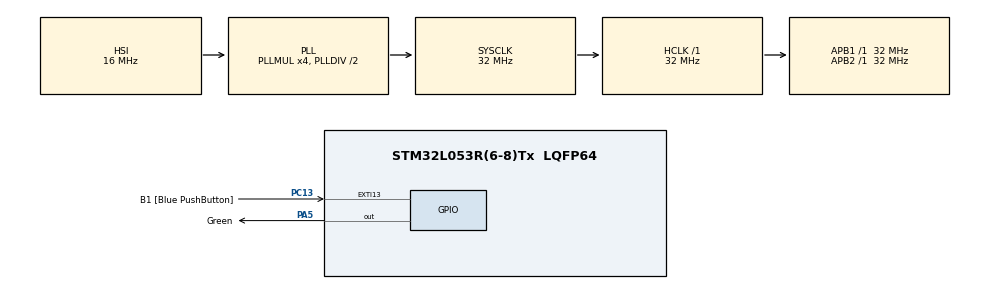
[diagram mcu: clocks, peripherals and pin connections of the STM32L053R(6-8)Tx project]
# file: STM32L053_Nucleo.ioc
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Mcu.Family=STM32L0
Mcu.Name=STM32L053R(6-8)Tx
Mcu.Package=LQFP64
PA13.GPIO_Label=TMS
PA13.Mode=Serial_Wire
PA13.Signal=SYS_SWDIO
PA14.GPIO_Label=TCK
PA14.Mode=Serial_Wire
PA14.Signal=SYS_SWCLK
PA2.GPIO_Label=USART_TX
PA2.Signal=USART2_TX
PA3.GPIO_Label=USART_RX
PA3.Signal=USART2_RX
PA5.GPIO_Label=Green
PA5.Signal=GPIO_Output
PC13.GPIO_Label=B1 [Blue PushButton]
PC13.GPIO_ModeDefaultEXTI=GPIO_MODE_IT_FALLING
PC13.Signal=GPXTI13
PC14-OSC32_IN.Signal=RCC_OSC32_IN
PC15-OSC32_OUT.Signal=RCC_OSC32_OUT
PH0-OSC_IN.Signal=RCC_OSC_IN
PH1-OSC_OUT.Signal=RCC_OSC_OUT
ProjectManager.HeapSize=0x200
ProjectManager.StackSize=0x400
ProjectManager.TargetToolchain=SW4STM32
RCC.AHBFreq_Value=32000000
RCC.APB1Freq_Value=32000000
RCC.APB1TimFreq_Value=32000000
RCC.APB2Freq_Value=32000000
RCC.APB2TimFreq_Value=32000000
RCC.HCLKFreq_Value=32000000
RCC.HSE_VALUE=8000000
RCC.HSI16_VALUE=16000000
RCC.HSI48_VALUE=48000000
RCC.HSI_VALUE=16000000
RCC.LSEState=RCC_LSE_ON
RCC.LSE_VALUE=32768
RCC.MSI_VALUE=2097000
RCC.PLLMUL=RCC_PLLMUL_4
RCC.SYSCLKFreq_VALUE=32000000
RCC.SYSCLKSource=RCC_SYSCLKSOURCE_PLLCLK
RCC.VCOOutputFreq_Value=64000000
board=NUCLEO-L053R8

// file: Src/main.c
/**
  ******************************************************************************
  * File Name          : main.c
  * Description        : Main program body
  ******************************************************************************
  ** This notice applies to any and all portions of this file
  * that are not between comment pairs USER CODE BEGIN and
  * USER CODE END. Other portions of this file, whether
  * inserted by the user or by software development tools
  * are owned by their respective copyright owners.
  *
  * COPYRIGHT(c) 2017 STMicroelectronics
  *
  * Redistribution and use in source and binary forms, with or without modification,
  * are permitted provided that the following conditions are met:
  *   1. Redistributions of source code must retain the above copyright notice,
  *      this list of conditions and the following disclaimer.
  *   2. Redistributions in binary form must reproduce the above copyright notice,
  *      this list of conditions and the following disclaimer in the documentation
  *      and/or other materials provided with the distribution.
  *   3. Neither the name of STMicroelectronics nor the names of its contributors
  *      may be used to endorse or promote products derived from this software
  *      without specific prior written permission.
  *
  * THIS SOFTWARE IS PROVIDED BY THE COPYRIGHT HOLDERS AND CONTRIBUTORS "AS IS"
  * AND ANY EXPRESS OR IMPLIED WARRANTIES, INCLUDING, BUT NOT LIMITED TO, THE
  * IMPLIED WARRANTIES OF MERCHANTABILITY AND FITNESS FOR A PARTICULAR PURPOSE ARE
  * DISCLAIMED. IN NO EVENT SHALL THE COPYRIGHT HOLDER OR CONTRIBUTORS BE LIABLE
  * FOR ANY DIRECT, INDIRECT, INCIDENTAL, SPECIAL, EXEMPLARY, OR CONSEQUENTIAL
  * DAMAGES (INCLUDING, BUT NOT LIMITED TO, PROCUREMENT OF SUBSTITUTE GOODS OR
  * SERVICES; LOSS OF USE, DATA, OR PROFITS; OR BUSINESS INTERRUPTION) HOWEVER
  * CAUSED AND ON ANY THEORY OF LIABILITY, WHETHER IN CONTRACT, STRICT LIABILITY,
  * OR TORT (INCLUDING NEGLIGENCE OR OTHERWISE) ARISING IN ANY WAY OUT OF THE USE
  * OF THIS SOFTWARE, EVEN IF ADVISED OF THE POSSIBILITY OF SUCH DAMAGE.
  *
  ******************************************************************************
  */
#include "main.h"
#include "stm32l0xx_hal.h"

/* USER CODE BEGIN PV */
/* Private variables ---------------------------------------------------------*/

/* USER CODE END PV */

void SystemClock_Config(void);
static void MX_GPIO_Init(void);

/* USER CODE BEGIN PFP */
/* Private function prototypes -----------------------------------------------*/

/* USER CODE END PFP */

int main(void)
{

  /* MCU Configuration----------------------------------------------------------*/

  /* Reset of all peripherals, Initializes the Flash interface and the Systick. */
  HAL_Init();

  /* Configure the system clock */
  SystemClock_Config();

  /* Initialize all configured peripherals */
  MX_GPIO_Init();

  /* Infinite loop */
  /* USER CODE BEGIN WHILE */
  while (1)
  {

	  HAL_GPIO_TogglePin(Green_GPIO_Port, Green_Pin);
	  HAL_Delay(75);
  /* USER CODE END WHILE */

  }

}

/** System Clock Configuration
*/
void SystemClock_Config(void)
{

  RCC_OscInitTypeDef RCC_OscInitStruct;
  RCC_ClkInitTypeDef RCC_ClkInitStruct;

    /**Configure the main internal regulator output voltage
    */
  __HAL_PWR_VOLTAGESCALING_CONFIG(PWR_REGULATOR_VOLTAGE_SCALE1);

    /**Initializes the CPU, AHB and APB busses clocks
    */
  RCC_OscInitStruct.OscillatorType = RCC_OSCILLATORTYPE_HSI;
  RCC_OscInitStruct.HSIState = RCC_HSI_ON;
  RCC_OscInitStruct.HSICalibrationValue = 16;
  RCC_OscInitStruct.PLL.PLLState = RCC_PLL_ON;
  RCC_OscInitStruct.PLL.PLLSource = RCC_PLLSOURCE_HSI;
  RCC_OscInitStruct.PLL.PLLMUL = RCC_PLLMUL_4;
  RCC_OscInitStruct.PLL.PLLDIV = RCC_PLLDIV_2;
  if (HAL_RCC_OscConfig(&RCC_OscInitStruct) != HAL_OK)
  {
    _Error_Handler(__FILE__, __LINE__);
  }

    /**Initializes the CPU, AHB and APB busses clocks
    */
  RCC_ClkInitStruct.ClockType = RCC_CLOCKTYPE_HCLK|RCC_CLOCKTYPE_SYSCLK
                              |RCC_CLOCKTYPE_PCLK1|RCC_CLOCKTYPE_PCLK2;
  RCC_ClkInitStruct.SYSCLKSource = RCC_SYSCLKSOURCE_PLLCLK;
  RCC_ClkInitStruct.AHBCLKDivider = RCC_SYSCLK_DIV1;
  RCC_ClkInitStruct.APB1CLKDivider = RCC_HCLK_DIV1;
  RCC_ClkInitStruct.APB2CLKDivider = RCC_HCLK_DIV1;

  if (HAL_RCC_ClockConfig(&RCC_ClkInitStruct, FLASH_LATENCY_1) != HAL_OK)
  {
    _Error_Handler(__FILE__, __LINE__);
  }

    /**Configure the Systick interrupt time
    */
  HAL_SYSTICK_Config(HAL_RCC_GetHCLKFreq()/1000);

    /**Configure the Systick
    */
  HAL_SYSTICK_CLKSourceConfig(SYSTICK_CLKSOURCE_HCLK);

  /* SysTick_IRQn interrupt configuration */
  HAL_NVIC_SetPriority(SysTick_IRQn, 0, 0);
}

/** Configure pins as
        * Analog
        * Input
        * Output
        * EVENT_OUT
        * EXTI
     PA2   ------> USART2_TX
     PA3   ------> USART2_RX
*/
static void MX_GPIO_Init(void)
{

  GPIO_InitTypeDef GPIO_InitStruct;

  /* GPIO Ports Clock Enable */
  __HAL_RCC_GPIOC_CLK_ENABLE();
  __HAL_RCC_GPIOH_CLK_ENABLE();
  __HAL_RCC_GPIOA_CLK_ENABLE();

  /*Configure GPIO pin Output Level */
  HAL_GPIO_WritePin(Green_GPIO_Port, Green_Pin, GPIO_PIN_RESET);

  /*Configure GPIO pin : B1_Pin */
  GPIO_InitStruct.Pin = B1_Pin;
  GPIO_InitStruct.Mode = GPIO_MODE_IT_FALLING;
  GPIO_InitStruct.Pull = GPIO_NOPULL;
  HAL_GPIO_Init(B1_GPIO_Port, &GPIO_InitStruct);

  /*Configure GPIO pins : USART_TX_Pin USART_RX_Pin */
  GPIO_InitStruct.Pin = USART_TX_Pin|USART_RX_Pin;
  GPIO_InitStruct.Mode = GPIO_MODE_AF_PP;
  GPIO_InitStruct.Pull = GPIO_NOPULL;
  GPIO_InitStruct.Speed = GPIO_SPEED_FREQ_VERY_HIGH;
  GPIO_InitStruct.Alternate = GPIO_AF4_USART2;
  HAL_GPIO_Init(GPIOA, &GPIO_InitStruct);

  /*Configure GPIO pin : Green_Pin */
  GPIO_InitStruct.Pin = Green_Pin;
  GPIO_InitStruct.Mode = GPIO_MODE_OUTPUT_PP;
  GPIO_InitStruct.Pull = GPIO_NOPULL;
  GPIO_InitStruct.Speed = GPIO_SPEED_FREQ_LOW;
  HAL_GPIO_Init(Green_GPIO_Port, &GPIO_InitStruct);

}

void _Error_Handler(char * file, int line)
{
  while(1)
  {
  }
}

/************************ (C) COPYRIGHT STMicroelectronics *****END OF FILE****/
